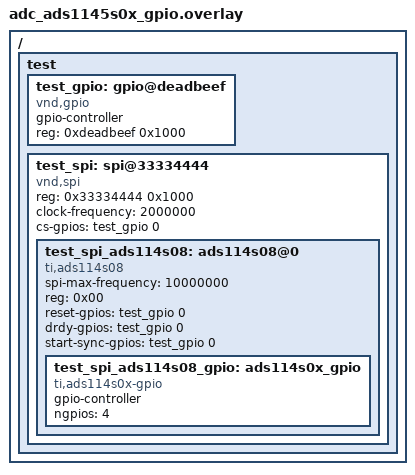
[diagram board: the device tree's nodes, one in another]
/*
 * Copyright (c) 2024 TOKITA Hiroshi
 *
 * SPDX-License-Identifier: Apache-2.0
 */

/ {
	test {
		#address-cells = <1>;
		#size-cells = <1>;

		test_gpio: gpio@deadbeef {
			compatible = "vnd,gpio";
			gpio-controller;
			reg = <0xdeadbeef 0x1000>;
			#gpio-cells = <0x2>;
			status = "okay";
		};

		test_spi: spi@33334444 {
			#address-cells = <1>;
			#size-cells = <0>;
			compatible = "vnd,spi";
			reg = <0x33334444 0x1000>;
			status = "okay";
			clock-frequency = <2000000>;

			cs-gpios = <&test_gpio 0 0>;

			test_spi_ads114s08: ads114s08@0 {
				compatible = "ti,ads114s08";
				status = "okay";
				spi-max-frequency = <10000000>;
				reg = <0x00>;
				#address-cells = <1>;
				#size-cells = <0>;
				#io-channel-cells = <1>;
				reset-gpios = <&test_gpio 0 0>;
				drdy-gpios = <&test_gpio 0 0>;
				start-sync-gpios = <&test_gpio 0 0>;

				test_spi_ads114s08_gpio: ads114s0x_gpio {
					compatible = "ti,ads114s0x-gpio";
					gpio-controller;
					ngpios = <4>;
					#gpio-cells = <2>;
				};
			};
		};
	};
};
